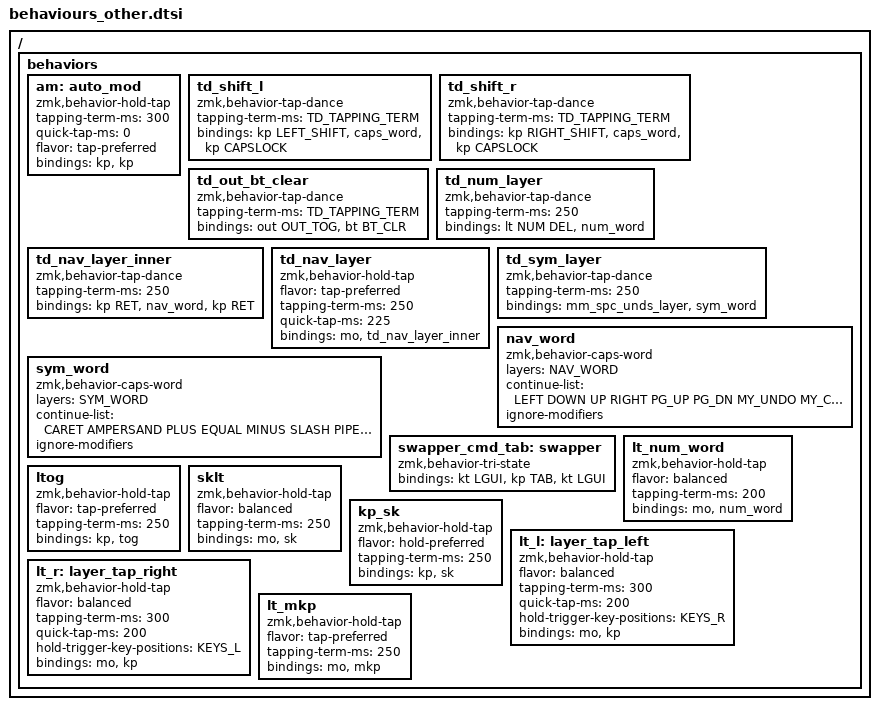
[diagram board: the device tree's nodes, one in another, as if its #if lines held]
#include <dt-bindings/zmk/outputs.h>

#define TD_TAPPING_TERM 300

/ {

    behaviors {

        /*
         * Auto Mod
         *
         * Usage: &am RPAR LPAR
         * Tap: (
         * Hold: )
         *
         * --
         *
         * Auto Shift
         *
         * Usage: AS(A)
         * Tap: a
         * Hold: A (shifted 'a')
         */

        am: auto_mod {
            compatible = "zmk,behavior-hold-tap";
            #binding-cells = <2>;
            tapping-term-ms = <300>;
            quick-tap-ms = <0>;
            flavor = "tap-preferred";
            bindings = <&kp>, <&kp>;
        };
        #define AM(hold_keycode, tap_keycode) &am hold_keycode tap_keycode
        #define AS(keycode) &am LS(keycode) keycode


        /*
        * Tap dancing shift
        *
        * Usage: &td_shift_l / &td_shift_r
        * Hold: Shift
        * Double Tap: Caps Word
        * Triple Tap: Caps Lock
        */

        td_shift_l: td_shift_l {
            compatible = "zmk,behavior-tap-dance";
            #binding-cells = <0>;
            tapping-term-ms = <TD_TAPPING_TERM>;
            bindings = <&kp LEFT_SHIFT>, <&caps_word>, <&kp CAPSLOCK>;
        };

        td_shift_r: td_shift_r {
            compatible = "zmk,behavior-tap-dance";
            #binding-cells = <0>;
            tapping-term-ms = <TD_TAPPING_TERM>;
            bindings = <&kp RIGHT_SHIFT>, <&caps_word>, <&kp CAPSLOCK>;
        };


        /*
        * Double Tap to clear BT
        *
        * Usage: &td_out_bt_clear
        * Hold / Tap: Toggle output (USB or BT)
        * Double Tap: Clear BT
        */
        td_out_bt_clear: td_out_bt_clear {
            compatible = "zmk,behavior-tap-dance";
            #binding-cells = <0>;
            tapping-term-ms = <TD_TAPPING_TERM>;
            bindings = <&out OUT_TOG>, <&bt BT_CLR>;
        };


        /*
        * Tap dancing num layer
        *
        * Usage: &td_num_layer
        * Tap: DEL
        * Hold: NUM layer
        * Double Tap: NUM_WORD layer
        * Triple Tap: NUM layer toggled
        */
        td_num_layer: td_num_layer {
            compatible = "zmk,behavior-tap-dance";
            #binding-cells = <0>;
            tapping-term-ms = <250>;
            #ifdef HAS_UROB
                bindings = <&lt NUM DEL>, <&num_word>;
            #else
                bindings = <&lt NUM DEL>, <&tog NUM>;
            #endif
        };

        /*
        * Tap dancing nav layer
        *
        * Usage: &td_nav_layer NAV 0
        * Tap: RET
        * Double Tap: NAV_WORD layer
        * Triple-Tap-Hold: RET repeated
        * Hold: NAV layer
        */
        td_nav_layer_inner: td_nav_layer_inner {
            compatible = "zmk,behavior-tap-dance";
            #binding-cells = <0>;
            tapping-term-ms = <250>;
            #ifdef HAS_UROB
                bindings = <&kp RET>, <&nav_word>, <&kp RET>;
            #else
                bindings = <&kp RET>, <&tog NAV>, <&kp RET>;
            #endif
        };
        td_nav_layer: td_nav_layer {
            compatible = "zmk,behavior-hold-tap";
            #binding-cells = <2>;
            flavor = "tap-preferred";
            tapping-term-ms = <250>;
            quick-tap-ms = <225>;
            bindings = <&mo>, <&td_nav_layer_inner>;
        };

        /*
        * Tap dancing sym layer
        *
        * Usage: &td_sym_layer
        * Tap: DEL
        * Hold: NAV layer
        * Double Tap: SYM_WORD layer
        * Triple Tap: SYM layer toggled
        */
        td_sym_layer: td_sym_layer {
            compatible = "zmk,behavior-tap-dance";
            #binding-cells = <0>;
            tapping-term-ms = <250>;
            #ifdef HAS_UROB
                bindings = <&mm_spc_unds_layer>, <&sym_word>;
            #else
                bindings = <&mm_spc_unds_layer>, <&tog SYM>;
            #endif
        };

        #ifdef HAS_UROB
            nav_word: nav_word {
                compatible = "zmk,behavior-caps-word";
                #binding-cells = <0>;
                layers = <NAV_WORD>;
                continue-list = <
                    LEFT DOWN UP RIGHT
                    PG_UP PG_DN
                    MY_UNDO MY_CUT MY_COPY MY_PASTE
                >;
                ignore-modifiers;  // modifiers don't deactivate the layer
            };
        #else
            nav_word: nav_word {
                compatible = "zmk,behavior-none";
                #binding-cells = <0>;
            };
        #endif

        #ifdef HAS_UROB
            sym_word: sym_word {
                compatible = "zmk,behavior-caps-word";
                #binding-cells = <0>;
                layers = <SYM_WORD>;
                continue-list = <
                    CARET AMPERSAND PLUS EQUAL MINUS SLASH PIPE
                    TILDE PERCENT UNDERSCORE EXCLAMATION DOLLAR SEMICOLON
                    HASH COLON GRAVE ASTERISK BACKSLASH AT_SIGN
                    RPAR LPAR RBKT LBKT RBRC LBRC GT LT
                    BACKSPACE
                >;
                ignore-modifiers;  // modifiers don't deactivate the layer
            };
        #else
            sym_word: sym_word {
                compatible = "zmk,behavior-none";
                #binding-cells = <0>;
            };
        #endif


        #ifdef HAS_TRI_STATE
            /*
            * Swapper CMD + TAB
            *
            * Use CMD TAB app switcher with a single app press.
            * Requires ZMK PR #1366.
            */
            swapper_cmd_tab: swapper {
                compatible = "zmk,behavior-tri-state";
                #binding-cells = <0>;
                bindings = <&kt LGUI>, <&kp TAB>, <&kt LGUI>;
                //  ignored-key-positions = <x>;
            };
        #else
            swapper_cmd_tab: swapper {
                compatible = "zmk,behavior-none";
                #binding-cells = <0>;
            };
        #endif


        lt_num_word: lt_num_word {
            compatible = "zmk,behavior-hold-tap";
            #binding-cells = <2>;
            flavor = "balanced";
            tapping-term-ms = <200>;

            #ifdef HAS_UROB
                bindings = <&mo>, <&num_word>;
            #else
                bindings = <&mo>, <&tog>;
            #endif
        };

       /*
        * Layer Toggle
        *
        * Usage: &ltog LGUI NAV
        * Tap: Layer Toggle
        * Hold: Keypress
        */
        ltog: ltog {
            compatible = "zmk,behavior-hold-tap";
            #binding-cells = <2>;
            flavor = "tap-preferred";
            tapping-term-ms = <250>;
            bindings = <&kp>, <&tog>;
        };

       /*
        * Layer Sticky Key Tap Toggle
        *
        * Usage: &sklt NUM RSHFT
        * Tap: Sticky Key
        * Hold: Layer
        */
        sklt: sklt {
            compatible = "zmk,behavior-hold-tap";
            #binding-cells = <2>;
            flavor = "balanced";
            tapping-term-ms = <250>;
            bindings = <&mo>, <&sk>;
        };

       /*
        * Layer Sticky Key Tap Toggle
        *
        * Usage: &kp_sk RSHFT RSHFT
        * Tap: Sticky Key RSHIFT
        * Hold: Regular RSHIFT
        */
        kp_sk: kp_sk {
            compatible = "zmk,behavior-hold-tap";
            #binding-cells = <2>;
            flavor = "hold-preferred";
            tapping-term-ms = <250>;
            bindings = <&kp>, <&sk>;
        };

       /*
        * Timerless Layer Tap
        *
        * Works similarly timerless homerow mods. It activates the
        * layer hold immediately for keys on the right side.
        */
        lt_l: layer_tap_left {
            compatible = "zmk,behavior-hold-tap";
            #binding-cells = <2>;
            flavor = "balanced";
            tapping-term-ms = <300>;
			quick-tap-ms = <200>;

            // Activate layer function immediately if a key on the right
            // side of the keyboard is used.
            hold-trigger-key-positions = <KEYS_R>;

            bindings = <&mo>, <&kp>;
        };

        lt_r: layer_tap_right {
            compatible = "zmk,behavior-hold-tap";
            #binding-cells = <2>;
            flavor = "balanced";
            tapping-term-ms = <300>;
			quick-tap-ms = <200>;

            // Activate layer function immediately if a key on the left
            // side of the keyboard is used.
            hold-trigger-key-positions = <KEYS_L>;

            bindings = <&mo>, <&kp>;
        };

       /*
        * Layer & mouse key
        *
        * Usage: &lt_mkp NUM RCLK
        * Tap: Mouse RCLK
        * Hold: Layer NUM
        */
        lt_mkp: lt_mkp {
            compatible = "zmk,behavior-hold-tap";
            #binding-cells = <2>;
            flavor = "tap-preferred";
            tapping-term-ms = <250>;
            bindings = <&mo>, <&mkp>;
        };
    };
};
